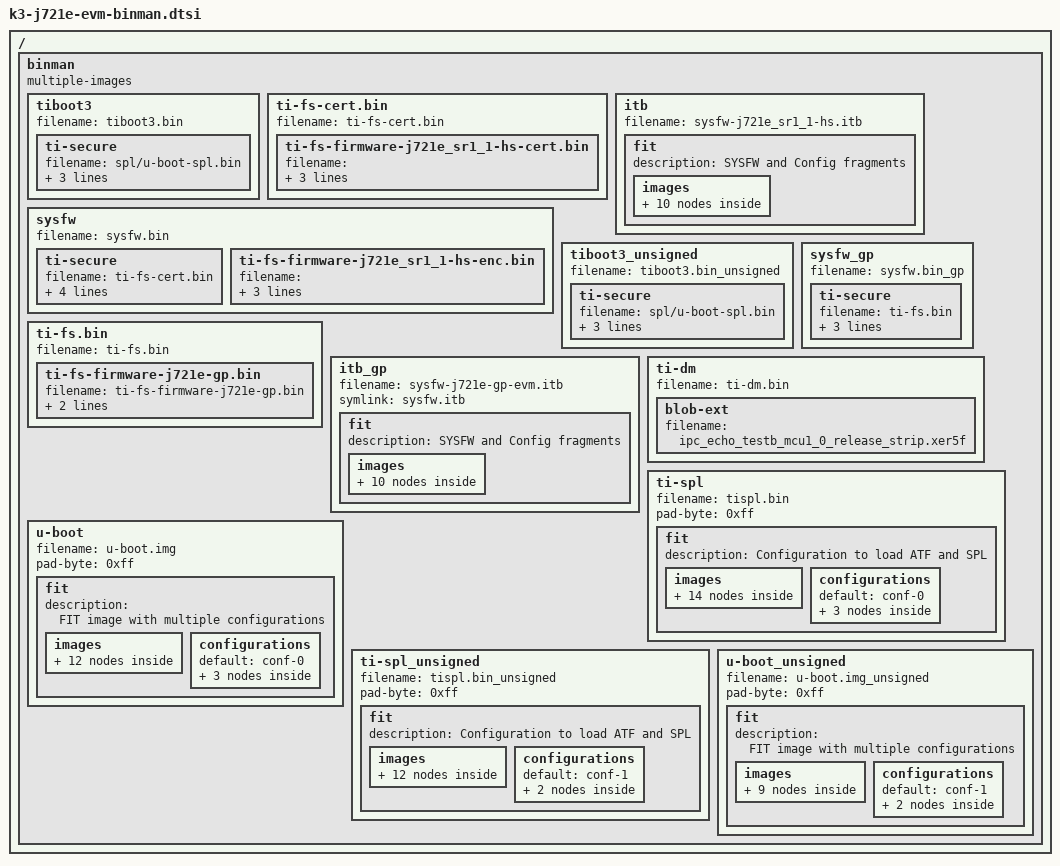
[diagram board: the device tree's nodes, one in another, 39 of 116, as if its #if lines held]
// SPDX-License-Identifier: GPL-2.0
/*
 * Copyright (C) 2021 Texas Instruments Incorporated - https://www.ti.com/
 */

/ {
	binman: binman {
		multiple-images;
	};
};

#ifdef CONFIG_TARGET_J721E_R5_EVM

&binman {
	tiboot3 {
		filename = "tiboot3.bin";
		ti-secure {
			filename = "spl/u-boot-spl.bin";
			core = <16>;
			load = <CONFIG_SPL_TEXT_BASE>;
			key = "/keys/custMpk.pem";
		};
	};
	ti-fs-cert.bin {
		filename = "ti-fs-cert.bin";
		ti-fs-firmware-j721e_sr1_1-hs-cert.bin {
			filename = "ti-fs-firmware-j721e_sr1_1-hs-cert.bin";
			type = "blob-ext";
			optional;
		};
	};
	sysfw {
		filename = "sysfw.bin";
		ti-secure {
			filename = "ti-fs-cert.bin";
			core = <0>;
			load = <0x40000>;
			key = "/keys/custMpk.pem";
			sysfw-cert;
		};
		ti-fs-firmware-j721e_sr1_1-hs-enc.bin {
			filename = "ti-fs-firmware-j721e_sr1_1-hs-enc.bin";
			type = "blob-ext";
			optional;
		};
	};
	itb {
		filename = "sysfw-j721e_sr1_1-hs.itb";
		fit {
			description = "SYSFW and Config fragments";
			#address-cells = <1>;
			images {
				sysfw.bin {
					description = "sysfw";
					type = "firmware";
					arch = "arm";
					compression = "none";
					blob-ext {
					    filename = "sysfw.bin";
					};
				};
				board-cfg.bin {
					description = "board-cfg";
					type = "firmware";
					arch = "arm";
					compression = "none";
					ti-secure {
						filename = "board-cfg.bin";
						secure;
					};
				};
				pm-cfg.bin {
					description = "pm-cfg";
					type = "firmware";
					arch = "arm";
					compression = "none";
					ti-secure {
						filename = "pm-cfg.bin";
						secure;
					};
				};
				rm-cfg.bin {
					description = "rm-cfg";
					type = "firmware";
					arch = "arm";
					compression = "none";
					ti-secure {
						filename = "rm-cfg.bin";
						secure;
					};
				};
				sec-cfg.bin {
					description = "sec-cfg";
					type = "firmware";
					arch = "arm";
					compression = "none";
					ti-secure {
						filename = "sec-cfg.bin";
						secure;
					};
				};
			};
		};
	};
};

&binman {
	tiboot3_unsigned {
		filename = "tiboot3.bin_unsigned";
		ti-secure {
			filename = "spl/u-boot-spl.bin";
			core = <16>;
			load = <CONFIG_SPL_TEXT_BASE>;
			sw-rev = <CONFIG_K3_X509_SWRV>;
		};
	};
	ti-fs.bin {
		filename = "ti-fs.bin";
		ti-fs-firmware-j721e-gp.bin {
			filename = "ti-fs-firmware-j721e-gp.bin";
			type = "blob-ext";
			optional;
		};
	};
	sysfw_gp {
		filename = "sysfw.bin_gp";
		ti-secure {
			filename = "ti-fs.bin";
			core = <0>;
			load = <0x40000>;
			sw-rev = <CONFIG_K3_X509_SWRV>;
		};
	};
	itb_gp {
		filename = "sysfw-j721e-gp-evm.itb";
		symlink = "sysfw.itb";
		fit {
			description = "SYSFW and Config fragments";
			#address-cells = <1>;
			images {
				sysfw.bin {
					description = "sysfw";
					type = "firmware";
					arch = "arm";
					compression = "none";
					blob-ext {
					    filename = "sysfw.bin_gp";
					};
				};
				board-cfg.bin {
					description = "board-cfg";
					type = "firmware";
					arch = "arm";
					compression = "none";
					blob-ext {
						filename = "board-cfg.bin";
					};
				};
				pm-cfg.bin {
					description = "pm-cfg";
					type = "firmware";
					arch = "arm";
					compression = "none";
					blob-ext {
						filename = "pm-cfg.bin";
					};
				};
				rm-cfg.bin {
					description = "rm-cfg";
					type = "firmware";
					arch = "arm";
					compression = "none";
					blob-ext {
						filename = "rm-cfg.bin";
					};
				};
				sec-cfg.bin {
					description = "sec-cfg";
					type = "firmware";
					arch = "arm";
					compression = "none";
					blob-ext {
						filename = "sec-cfg.bin";
					};
				};
			};
		};
	};
};
#endif

#ifdef CONFIG_TARGET_J721E_A72_EVM

#define SPL_NODTB "spl/u-boot-spl-nodtb.bin"
#define SPL_J721E_EVM_DTB "spl/dts/k3-j721e-common-proc-board.dtb"
#define SPL_J721E_TPS_DTB "spl/dts/k3-j721e-tps65917-proc-board.dtb"
#define SPL_J721E_SK_DTB "spl/dts/k3-j721e-sk.dtb"

#define UBOOT_NODTB "u-boot-nodtb.bin"
#define J721E_EVM_DTB "arch/arm/dts/k3-j721e-common-proc-board.dtb"
#define J721E_TPS_DTB "arch/arm/dts/k3-j721e-tps65917-proc-board.dtb"
#define J721E_SK_DTB "arch/arm/dts/k3-j721e-sk.dtb"

&binman {
	ti-dm {
		filename = "ti-dm.bin";
		blob-ext {
			filename = "ipc_echo_testb_mcu1_0_release_strip.xer5f";
		};
	};
	ti-spl {
		filename = "tispl.bin";
		pad-byte = <0xff>;

		fit {
			description = "Configuration to load ATF and SPL";
			#address-cells = <1>;

			images {

				atf {
					description = "ARM Trusted Firmware";
					type = "firmware";
					arch = "arm64";
					compression = "none";
					os = "arm-trusted-firmware";
					load = <CONFIG_K3_ATF_LOAD_ADDR>;
					entry = <CONFIG_K3_ATF_LOAD_ADDR>;
					atf-bl31 {
					};
				};

				tee {
					description = "OPTEE";
					type = "tee";
					arch = "arm64";
					compression = "none";
					os = "tee";
					load = <0x9e800000>;
					entry = <0x9e800000>;
					tee-os {
					};
				};

				dm {
					description = "DM binary";
					type = "firmware";
					arch = "arm32";
					compression = "none";
					os = "DM";
					load = <0x89000000>;
					entry = <0x89000000>;
					blob-ext {
						filename = "ti-dm.bin";
					};
				};

				spl {
					description = "SPL (64-bit)";
					type = "standalone";
					os = "U-Boot";
					arch = "arm64";
					compression = "none";
					load = <CONFIG_SPL_TEXT_BASE>;
					entry = <CONFIG_SPL_TEXT_BASE>;
					ti-secure {
						filename = SPL_NODTB;
						secure;
					};
				};

				fdt-0 {
					description = "k3-j721e-common-proc-board";
					type = "flat_dt";
					arch = "arm";
					compression = "none";
					ti-secure {
						filename = SPL_J721E_EVM_DTB;
						secure;
					};
				};

				fdt-1 {
					description = "k3-j721e-tps65917-proc-board";
					arch = "arm";
					compression = "none";
					ti-secure {
						filename = SPL_J721E_TPS_DTB;
						secure;
					};
				};

				fdt-2 {
					description = "k3-j721e-sk";
					type = "flat_dt";
					arch = "arm";
					compression = "none";
					ti-secure {
						filename = SPL_J721E_SK_DTB;
						secure;
					};
				};
			};

			configurations {
				default = "conf-0";

				conf-0 {
					description = "k3-j721e-common-proc-board";
					firmware = "atf";
					loadables = "tee", "dm", "spl";
					fdt = "fdt-0";
				};

				conf-1 {
					description = "k3-j721e-tps65917-proc-board";
					firmware = "atf";
					loadables = "tee", "dm", "spl";
					fdt = "fdt-1";
				};

				conf-2 {
					description = "k3-j721e-sk";
					firmware = "atf";
					loadables = "tee", "dm", "spl";
					fdt = "fdt-2";
				};
			};
		};
	};
};

&binman {
	u-boot {
		filename = "u-boot.img";
		pad-byte = <0xff>;

		fit {
			description = "FIT image with multiple configurations";

			images {
				uboot {
					description = "U-Boot for j721e board";
					type = "firmware";
					os = "u-boot";
					arch = "arm";
					compression = "none";
					load = <CONFIG_TEXT_BASE>;
					ti-secure {
						filename = UBOOT_NODTB;
						secure;
					};
					hash {
						algo = "crc32";
					};
				};

				fdt-0 {
					description = "k3-j721e-common-proc-board";
					type = "flat_dt";
					arch = "arm";
					compression = "none";
					ti-secure {
						filename = J721E_EVM_DTB;
						secure;
					};
					hash {
						algo = "crc32";
					};
				};

				fdt-1 {
					description = "k3-j721e-tps65917-proc-board";
					type = "flat_dt";
					arch = "arm";
					compression = "none";
					ti-secure {
						filename = J721E_TPS_DTB;
						secure;
					};
					hash {
						algo = "crc32";
					};
				};

				fdt-2 {
					description = "k3-j721e-sk";
					type = "flat_dt";
					arch = "arm";
					compression = "none";
					ti-secure {
						filename = J721E_SK_DTB;
						secure;
					};
					hash {
						algo = "crc32";
					};
				};
			};

			configurations {
				default = "conf-0";

				conf-0 {
					description = "k3-j721e-common-proc-board";
					firmware = "uboot";
					loadables = "uboot";
					fdt = "fdt-0";
				};

				conf-1 {
					description = "k3-j721e-tps65917-proc-board";
					firmware = "uboot";
					loadables = "uboot";
					fdt = "fdt-1";
				};

				conf-2 {
					description = "k3-j721e-sk";
					firmware = "uboot";
					loadables = "uboot";
					fdt = "fdt-2";
				};
			};
		};
	};
};

&binman {
	ti-spl_unsigned {
		filename = "tispl.bin_unsigned";
		pad-byte = <0xff>;

		fit {
			description = "Configuration to load ATF and SPL";
			#address-cells = <1>;

			images {

				atf {
					description = "ARM Trusted Firmware";
					type = "firmware";
					arch = "arm64";
					compression = "none";
					os = "arm-trusted-firmware";
					load = <CONFIG_K3_ATF_LOAD_ADDR>;
					entry = <CONFIG_K3_ATF_LOAD_ADDR>;
					atf-bl31 {
						filename = "bl31.bin";
					};
				};

				tee {
					description = "OPTEE";
					type = "tee";
					arch = "arm64";
					compression = "none";
					os = "tee";
					load = <0x9e800000>;
					entry = <0x9e800000>;
					tee-os {
						filename = "tee-pager_v2.bin";
					};
				};

				dm {
					description = "DM binary";
					type = "firmware";
					arch = "arm32";
					compression = "none";
					os = "DM";
					load = <0x89000000>;
					entry = <0x89000000>;
					blob-ext {
						filename = "ti-dm.bin";
					};
				};

				spl {
					description = "SPL (64-bit)";
					type = "standalone";
					os = "U-Boot";
					arch = "arm64";
					compression = "none";
					load = <CONFIG_SPL_TEXT_BASE>;
					entry = <CONFIG_SPL_TEXT_BASE>;
					blob {
						filename = "spl/u-boot-spl-nodtb.bin";
					};
				};

				fdt-1 {
					description = "k3-j721e-common-proc-board";
					type = "flat_dt";
					arch = "arm";
					compression = "none";
					blob {
						filename = SPL_J721E_EVM_DTB;
					};
				};

				fdt-2 {
					description = "k3-j721e-sk";
					type = "flat_dt";
					arch = "arm";
					compression = "none";
					blob {
						filename = SPL_J721E_SK_DTB;
					};
				};
			};

			configurations {
				default = "conf-1";

				conf-1 {
					description = "k3-j721e-common-proc-board";
					firmware = "atf";
					loadables = "tee", "dm", "spl";
					fdt = "fdt-1";
				};

				conf-2 {
					description = "k3-j721e-sk";
					firmware = "atf";
					loadables = "tee", "dm", "spl";
					fdt = "fdt-2";
				};
			};
		};
	};
};

&binman {
	u-boot_unsigned {
		filename = "u-boot.img_unsigned";
		pad-byte = <0xff>;

		fit {
			description = "FIT image with multiple configurations";

			images {
				uboot {
					description = "U-Boot for j721e board";
					type = "firmware";
					os = "u-boot";
					arch = "arm";
					compression = "none";
					load = <CONFIG_TEXT_BASE>;
					blob {
						filename = UBOOT_NODTB;
					};
					hash {
						algo = "crc32";
					};
				};

				fdt-1 {
					description = "k3-j721e-common-proc-board";
					type = "flat_dt";
					arch = "arm";
					compression = "none";
					blob {
						filename = J721E_EVM_DTB;
					};
					hash {
						algo = "crc32";
					};
				};

				fdt-2 {
					description = "k3-j721e-sk";
					type = "flat_dt";
					arch = "arm";
					compression = "none";
					blob {
						filename = J721E_SK_DTB;
					};
					hash {
						algo = "crc32";
					};
				};
			};

			configurations {
				default = "conf-1";

				conf-1 {
					description = "k3-j721e-common-proc-board";
					firmware = "uboot";
					loadables = "uboot";
					fdt = "fdt-1";
				};

				conf-2 {
					description = "k3-j721e-sk";
					firmware = "uboot";
					loadables = "uboot";
					fdt = "fdt-2";
				};
			};
		};
	};
};
#endif
